# PIC32CM5164JH00100 device description
Architecture: CORTEX-M0PLUS; Family: PIC32CM; Series: PIC32CMJH00
Registers are 32-bit, read-write, reset 0x0 unless marked. A register's access mark holds for its fields unless they carry their own. Offsets are from the block's base; [hi:lo] are bit positions; 'fields as' and 'values as' point back to an identical list.

## OTP2_FUSES — Non-Volatile Fuses
Instances: OTP2_FUSES 0x00806008 in fuses
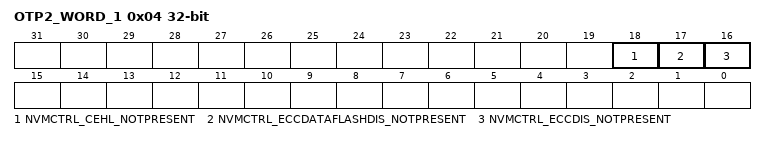
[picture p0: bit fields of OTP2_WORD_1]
0x04 OTP2_WORD_1 ro reset not defined — OTP2 Page Word 1
  [18] NVMCTRL_CEHL_NOTPRESENT — Allows the CEHL bit to be able to be used by the user to Chip Erase Hard Lock or disabled and no Chip Erase Hard lock allowed.
  [17] NVMCTRL_ECCDATAFLASHDIS_NOTPRESENT — Allows the ECC Data Flash disable bit (ECCCTRL.ECCDFDIS) to become not available for the user with a device fuse.
  [16] NVMCTRL_ECCDIS_NOTPRESENT — Allows the ECC disable bit (ECCCTRL.ECCDIS) to become not available for the user with a device fuse.

## OTP3_FUSES — Non-Volatile Fuses
Instances: OTP3_FUSES 0x00806010 in fuses
0x04 OTP3_WORD_1 ro reset not defined — OTP3 Page Word 1
  [31] NVMCTRL_DUMMY2 — Dummy for OTP3 entry

## OTP4_FUSES — Non-Volatile Fuses
Instances: OTP4_FUSES 0x00806018 in fuses
0x04 OTP4_WORD_1 ro reset not defined — OTP4 Page Word 1
  [31] NVMCTRL_DUMMY — Dummy for OTP4 entry

## OTP5_FUSES — Non-Volatile Fuses
Instances: OTP5_FUSES 0x00806020 in fuses
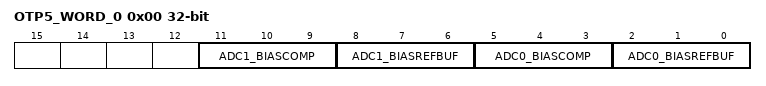
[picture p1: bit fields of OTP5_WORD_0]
0x00 OTP5_WORD_0 ro reset not defined — OTP5 Page Word 0
  [11:9] ADC1_BIASCOMP — ADC Comparator Scaling
  [8:6] ADC1_BIASREFBUF — ADC Bias Reference Buffer Scaling
  [5:3] ADC0_BIASCOMP — ADC Comparator Scaling
  [2:0] ADC0_BIASREFBUF — ADC Bias Reference Buffer Scaling

## USER_FUSES — Non-Volatile Fuses
Instances: USER_FUSES 0x00804000 in fuses
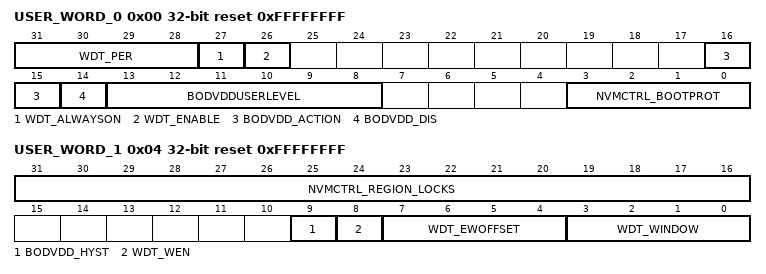
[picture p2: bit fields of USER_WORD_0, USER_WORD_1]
0x00 USER_WORD_0 reset 0xFFFFFFFF — USER Page Word 0
  [31:28] WDT_PER — WDT Period
    0=CYC8 (8 clock cycles); 1=CYC16 (16 clock cycles); 2=CYC32 (32 clock cycles); 3=CYC64 (64 clock cycles); 4=CYC128 (128 clock cycles); 5=CYC256 (256 clock cycles); 6=CYC512 (512 clock cycles); 7=CYC1024 (1024 clock cycles); 8=CYC2048 (2048 clock cycles); 9=CYC4096 (4096 clock cycles); 10=CYC8192 (8192 clock cycles); 11=CYC16384 (16384 clock cycles)
  [27] WDT_ALWAYSON
    0=DISABLED (WDT is enabled and disabled through ENABLE bit); 1=ENABLED (WDT is enabled and can only be disabled by a power-on reset)
  [26] WDT_ENABLE
    0=DISABLED (WDT is disabled on power on); 1=ENABLED (WDT is enabled on power on)
  [16:15] BODVDD_ACTION
    0=NONE (No action); 1=RESET (The BODVDD generates a reset); 2=INT (The BODVDD generates an interrupt)
  [14] BODVDD_DIS — BODVDD Disable
    0=ENABLED (BODVDD is enabled on power on); 1=DISABLED (BODVDD is disabled on power on)
  [13:8] BODVDDUSERLEVEL
  [3:0] NVMCTRL_BOOTPROT — Bootloader Size
    15=SIZE_0BYTES (0 Bytes); 14=SIZE_512BYTES (512 Bytes); 13=SIZE_1024BYTES (1024 Bytes); 12=SIZE_2048BYTES (2048 Bytes); 11=SIZE_4096BYTES (4096 Bytes); 10=SIZE_8192BYTES (8192 Bytes); 9=SIZE_16384BYTES (16384 Bytes); 8=SIZE_32768BYTES (32768 Bytes); 7=SIZE_40960BYTES (40960 Bytes); 6=SIZE_49152BYTES (49152 Bytes); 5=SIZE_57344BYTES (57344 Bytes); 4=SIZE_65536BYTES (65536 Bytes); 3=SIZE_73728BYTES (73728 Bytes); 2=SIZE_81920BYTES (81920 Bytes); 1=SIZE_90112BYTES (90112 Bytes); 0=SIZE_98304BYTES (98304 Bytes)
0x04 USER_WORD_1 reset 0xFFFFFFFF — USER Page Word 1
  [31:16] NVMCTRL_REGION_LOCKS — NVM Region lock bits
  [9] BODVDD_HYST — BODVDD Hysterisis
    0=DISABLED (No Hysteresis); 1=ENABLED (Hysteresis Enabled)
  [8] WDT_WEN — WDT Window Mode Enable
    0=DISABLED (WDT is disabled); 1=ENABLED (WDT is enabled)
  [7:4] WDT_EWOFFSET — WDT Early Warning Offset
    values as USER_WORD_0.WDT_PER
  [3:0] WDT_WINDOW
    values as USER_WORD_0.WDT_PER

## OSC32KCTRL — 32k Oscillators Control
Instances: OSC32KCTRL 0x40001400
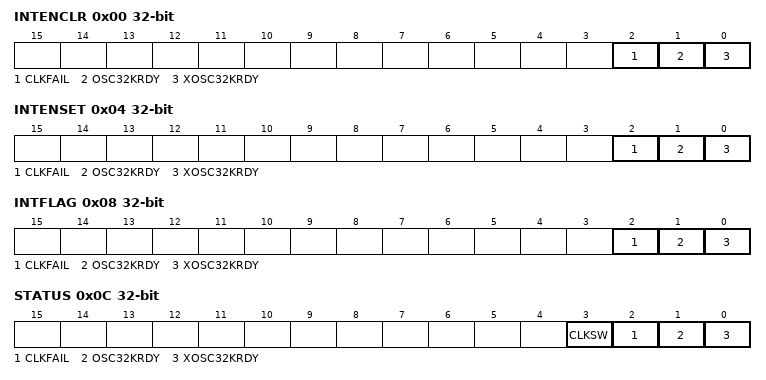
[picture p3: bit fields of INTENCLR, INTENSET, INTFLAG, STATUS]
0x00 INTENCLR (atomic clear) — Interrupt Enable Clear
  [2] CLKFAIL — XOSC32K Clock Failure Detector Interrupt Enable
  [1] OSC32KRDY — OSC32K Ready Interrupt Enable
  [0] XOSC32KRDY — XOSC32K Ready Interrupt Enable
0x04 INTENSET (atomic set) — Interrupt Enable Set
  fields as INTENCLR
0x08 INTFLAG (atomic clear) — Interrupt Flag Status and Clear
  [2] CLKFAIL — XOSC32K Clock Failure Detector
  [1] OSC32KRDY — OSC32K Ready
  [0] XOSC32KRDY — XOSC32K Ready
0x0C STATUS ro — Power and Clocks Status
  [3] CLKSW — XOSC32K Clock switch
  [2] CLKFAIL — XOSC32K Clock Failure Detector
  [1] OSC32KRDY — OSC32K Ready
  [0] XOSC32KRDY — XOSC32K Ready
0x10 RTCCTRL — RTC Clock Selection
  [2:0] RTCSEL
    0=ULP1K (1.024kHz from 32kHz internal ULP oscillator); 1=ULP32K (32.768kHz from 32kHz internal ULP oscillator); 2=OSC1K (1.024kHz from 32.768kHz internal oscillator); 3=OSC32K (32.768kHz from 32.768kHz internal oscillator); 4=XOSC1K (1.024kHz from 32.768kHz external crystal oscillator); 5=XOSC32K (32.768kHz from 32.768kHz external crystal oscillator)
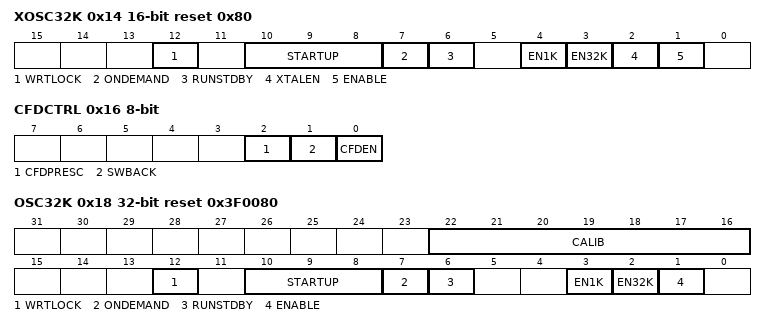
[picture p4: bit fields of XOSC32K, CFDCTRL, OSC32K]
0x14 XOSC32K 16-bit reset 0x80 — 32kHz External Crystal Oscillator (XOSC32K) Control
  [12] WRTLOCK — Write Lock
  [10:8] STARTUP — Oscillator Start-Up Time
    0=CYCLE1 (122 us); 1=CYCLE32 (1.06 ms); 2=CYCLE2048 (62.6 ms); 3=CYCLE4096 (125 ms); 4=CYCLE16384 (500 ms); 5=CYCLE32768 (1 s); 6=CYCLE65536 (2 s); 7=CYCLE131072 (4 s)
  [7] ONDEMAND — On Demand Control
  [6] RUNSTDBY — Run in Standby
  [4] EN1K — 1kHz Output Enable
  [3] EN32K — 32kHz Output Enable
  [2] XTALEN — Crystal Oscillator Enable
  [1] ENABLE — Oscillator Enable
0x16 CFDCTRL 8-bit — Clock Failure Detector Control
  [2] CFDPRESC — Clock Failure Detector Prescaler
  [1] SWBACK — Clock Switch Back Enable
  [0] CFDEN — Clock Failure Detector Enable
0x17 EVCTRL 8-bit — Event Control
  [0] CFDEO — Clock Failure Detector Event Output Enable
0x18 OSC32K reset 0x3F0080 — 32kHz Internal Oscillator (OSC32K) Control
  [22:16] CALIB — Oscillator Calibration
  [12] WRTLOCK — Write Lock
  [10:8] STARTUP — Oscillator Start-Up Time
    0=CYCLE3 (0.183 ms); 1=CYCLE4 (0.214 ms); 2=CYCLE6 (0.275 ms); 3=CYCLE10 (0.397 ms); 4=CYCLE18 (0.641 ms); 5=CYCLE34 (1.129 ms); 6=CYCLE66 (2.106 ms); 7=CYCLE130 (4.059 ms)
  [7] ONDEMAND — On Demand Control
  [6] RUNSTDBY — Run in Standby
  [3] EN1K — 1kHz Output Enable
  [2] EN32K — 32kHz Output Enable
  [1] ENABLE — Oscillator Enable
0x1C OSCULP32K reset not defined — 32kHz Ultra Low Power Internal Oscillator (OSCULP32K) Control
  [15] WRTLOCK — Write Lock

## Notices in the file
Copyright (c) 2019 Microchip Technology Inc.
SPDX-License-Identifier: Apache-2.0
Licensed under the Apache License, Version 2.0 (the "License");
you may not use this file except in compliance with the License.
You may obtain a copy of the License at
http://www.apache.org/licenses/LICENSE-2.0
Unless required by applicable law or agreed to in writing, software
distributed under the License is distributed on an "AS IS" BASIS,
WITHOUT WARRANTIES OR CONDITIONS OF ANY KIND, either express or implied.
See the License for the specific language governing permissions and
limitations under the License.
